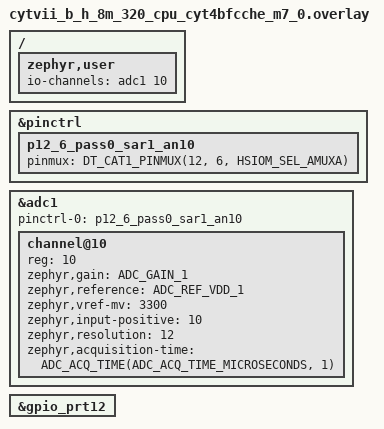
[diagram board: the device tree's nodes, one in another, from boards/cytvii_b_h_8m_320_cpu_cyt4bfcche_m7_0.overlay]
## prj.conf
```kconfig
CONFIG_ADC=y
# CONFIG_ADC_SHELL=y
# CONFIG_SHELL=y
# CONFIG_SHELL_PROMPT_UART="uart:~$ "
CONFIG_LOG=y
CONFIG_LOG_DEFAULT_LEVEL=3
CONFIG_ADC_LOG_LEVEL_WRN=y
CONFIG_COVERAGE=y

# Disable debug logging for noisy subsystems
CONFIG_MPU_LOG_LEVEL_DBG=n
CONFIG_KERNEL_LOG_LEVEL_DBG=n
CONFIG_ADC_ASYNC=n
```

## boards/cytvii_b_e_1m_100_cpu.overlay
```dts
#include <zephyr/dt-bindings/pinctrl/ifx_cat1-pinctrl.h>

/ {
	zephyr,user {
		io-channels = <&adc2 5>;
	};
};

&pinctrl {
	/* Configure P18.5 for analog input */
	p18_5_pass0_sar2_an14: p18_5_pass0_sar2_an14 {
		pinmux = <DT_CAT1_PINMUX(18, 5, HSIOM_SEL_AMUXA)>;
	};
};

&adc2 {
	#address-cells = <1>;
	#size-cells = <0>;

	pinctrl-0 = <&p18_5_pass0_sar2_an14>;
	pinctrl-names = "default";


	channel@5 {
		reg = <5>;
		zephyr,gain = "ADC_GAIN_1";
		zephyr,reference = "ADC_REF_VDD_1";
		zephyr,vref-mv = <3300>;  /* VDDA = 3.3V reference */

		zephyr,input-positive = <5>;
		zephyr,resolution = <12>;
		zephyr,acquisition-time = <ADC_ACQ_TIME(ADC_ACQ_TIME_MICROSECONDS, 1)>;
	};
};
```

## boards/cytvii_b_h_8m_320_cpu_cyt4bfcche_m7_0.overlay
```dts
/*
* Copyright (c) 2025 Linumiz GmbH
* SPDX-License-Identifier: Apache-2.0
*/

#include <zephyr/dt-bindings/pinctrl/ifx_cat1-pinctrl.h>

/ {
	zephyr,user {
		io-channels = <&adc1 10>;
	};
};

&pinctrl {
		/* Configure P12.6 for analog input */
		p12_6_pass0_sar1_an10: p12_6_pass0_sar1_an10 {
		pinmux = <DT_CAT1_PINMUX(12, 6, HSIOM_SEL_AMUXA)>;
		};
	};

&adc1 {
		#address-cells = <1>;
		#size-cells = <0>;
		pinctrl-0 = <&p12_6_pass0_sar1_an10>;
		pinctrl-names = "default";

channel@10 {
		reg = <10>;
		zephyr,gain = "ADC_GAIN_1";
		zephyr,reference = "ADC_REF_VDD_1";
		zephyr,vref-mv = <3300>;
		zephyr,input-positive = <10>;
		zephyr,resolution = <12>;
		zephyr,acquisition-time = <ADC_ACQ_TIME(ADC_ACQ_TIME_MICROSECONDS, 1)>;
	};
};

&gpio_prt12 {
	status = "okay";
};
```

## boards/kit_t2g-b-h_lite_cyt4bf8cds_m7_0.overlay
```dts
/*
 * Copyright (c) 2025 Linumiz GmbH
 * SPDX-License-Identifier: Apache-2.0
 */

#include <zephyr/dt-bindings/pinctrl/ifx_cat1-pinctrl.h>

/ {
    zephyr,user {
        io-channels = <&adc0 0>;
    };
};

&pinctrl {
    /* Configure P6.0 (VR1 Potentiometer) for analog input */
    p6_0_pass0_sar0_an0: p6_0_pass0_sar0_an0 {
        pinmux = <DT_CAT1_PINMUX(6, 0, HSIOM_SEL_AMUXA)>;
    };
};

&adc0 {
    #address-cells = <1>;
    #size-cells = <0>;

    pinctrl-0 = <&p6_0_pass0_sar0_an0>;
    pinctrl-names = "default";


    channel@0 {
        reg = <0>;
        zephyr,gain = "ADC_GAIN_1";
        zephyr,reference = "ADC_REF_VDD_1";
        zephyr,vref-mv = <3300>;  /* VDDA = 3.3V reference */

        zephyr,input-positive = <0>;  /* AN0 mapped to P6.0 (Potentiometer VR1) */ 
        zephyr,resolution = <12>;
        zephyr,acquisition-time = <ADC_ACQ_TIME(ADC_ACQ_TIME_MICROSECONDS, 1)>;
    };
};
```

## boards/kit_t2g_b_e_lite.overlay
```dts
/*
 * Copyright (c) 2025 Linumiz GmbH
 * SPDX-License-Identifier: Apache-2.0
 */

#include <zephyr/dt-bindings/pinctrl/ifx_cat1-pinctrl.h>
#include <zephyr/dt-bindings/adc/adc.h>

/ {
    zephyr,user {
        io-channels = <&adc0 0>;
    };
};

&pinctrl {
    /* Configure P6.0 for analog input */
    p6_0_pass0_sar0_an14: p6_6_pass0_sar0_an14 {
        pinmux = <DT_CAT1_PINMUX(6, 0, HSIOM_SEL_AMUXA)>;
    };
};

&adc0 {
    #address-cells = <1>;
    #size-cells = <0>;

    pinctrl-0 = <&p6_0_pass0_sar0_an14>;
    pinctrl-names = "default";


    channel@0 {
        reg = <0>;
        zephyr,gain = "ADC_GAIN_1";
        zephyr,reference = "ADC_REF_VDD_1";
        zephyr,vref-mv = <3300>;  /* VDDA = 3.3V reference */

        zephyr,input-positive = <0>;
        zephyr,resolution = <12>;
        zephyr,acquisition-time = <ADC_ACQ_TIME(ADC_ACQ_TIME_MICROSECONDS, 1)>;
    };
};
```

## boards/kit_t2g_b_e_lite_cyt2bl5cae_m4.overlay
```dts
/*
 * Copyright (c) 2025 Linumiz GmbH
 * SPDX-License-Identifier: Apache-2.0
 */

#include <zephyr/dt-bindings/pinctrl/ifx_cat1-pinctrl.h>
#include <zephyr/dt-bindings/adc/adc.h>

/ {
	zephyr,user {
		io-channels = <&adc0 0>;
	};
};

&pinctrl {
	/* Configure P6.0 for analog input */
	p6_0_pass0_sar0_an14: p6_6_pass0_sar0_an14 {
		pinmux = <DT_CAT1_PINMUX(6, 0, HSIOM_SEL_AMUXA)>;
	};
};

&adc0 {
	#address-cells = <1>;
	#size-cells = <0>;

	pinctrl-0 = <&p6_0_pass0_sar0_an14>;
	pinctrl-names = "default";


	channel@0 {
		reg = <0>;
		zephyr,gain = "ADC_GAIN_1";
		zephyr,reference = "ADC_REF_VDD_1";
		zephyr,vref-mv = <3300>;  /* VDDA = 3.3V reference */

		zephyr,input-positive = <0>;
		zephyr,resolution = <12>;
		zephyr,acquisition-time = <ADC_ACQ_TIME(ADC_ACQ_TIME_MICROSECONDS, 1)>;
	};
};
```

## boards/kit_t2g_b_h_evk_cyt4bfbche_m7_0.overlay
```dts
/*
 * Copyright (c) 2025 Linumiz GmbH
 * SPDX-License-Identifier: Apache-2.0
 */

#include <zephyr/dt-bindings/pinctrl/ifx_cat1-pinctrl.h>

/ {
    zephyr,user {
        io-channels = <&adc0 0>;
    };
};

&pinctrl {
    /* Configure P6.6 for analog input */
    p6_6_pass0_sar0_an14: p6_6_pass0_sar0_an14 {
        pinmux = <DT_CAT1_PINMUX(6, 6, HSIOM_SEL_AMUXA)>;
    };
};

&adc0 {
    #address-cells = <1>;
    #size-cells = <0>;

    pinctrl-0 = <&p6_6_pass0_sar0_an14>;
    pinctrl-names = "default";


    channel@0 {
        reg = <0>;
        zephyr,gain = "ADC_GAIN_1";
        zephyr,reference = "ADC_REF_VDD_1";
        zephyr,vref-mv = <3300>;  /* VDDA = 3.3V reference */

        zephyr,input-positive = <6>;
        zephyr,resolution = <12>;
        zephyr,acquisition-time = <ADC_ACQ_TIME(ADC_ACQ_TIME_MICROSECONDS, 1)>;
    };
};
```

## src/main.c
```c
/*
 * Copyright (c) 2020 Libre Solar Technologies GmbH
 *
 * SPDX-License-Identifier: Apache-2.0
 */

#include <inttypes.h>
#include <stddef.h>
#include <stdint.h>

#include <zephyr/device.h>
#include <zephyr/devicetree.h>
#include <zephyr/drivers/adc.h>
#include <zephyr/kernel.h>
#include <zephyr/sys/printk.h>
#include <zephyr/sys/util.h>

#if !DT_NODE_EXISTS(DT_PATH(zephyr_user)) || \
	!DT_NODE_HAS_PROP(DT_PATH(zephyr_user), io_channels)
#error "No suitable devicetree overlay specified"
#endif

#define DT_SPEC_AND_COMMA(node_id, prop, idx) \
	ADC_DT_SPEC_GET_BY_IDX(node_id, idx),

/* Data of ADC io-channels specified in devicetree. */
static const struct adc_dt_spec adc_channels[] = {
	DT_FOREACH_PROP_ELEM(DT_PATH(zephyr_user), io_channels,
			     DT_SPEC_AND_COMMA)
};

int main(void)
{
	int err;
	uint32_t count = 0;
	uint32_t buf;
	struct adc_sequence sequence = {
		.buffer = &buf,
		/* buffer size in bytes, not number of samples */
		.buffer_size = sizeof(buf),
	};

	/* Configure channels individually prior to sampling. */
	for (size_t i = 0U; i < ARRAY_SIZE(adc_channels); i++) {
		if (!adc_is_ready_dt(&adc_channels[i])) {
			printk("ADC controller device %s not ready\n", adc_channels[i].dev->name);
			return 0;
		}

		err = adc_channel_setup_dt(&adc_channels[i]);
		if (err < 0) {
			printk("Could not setup channel #%d (%d)\n", i, err);
			return 0;
		}
	}

#ifndef CONFIG_COVERAGE
	while (1) {
#else
	for (int k = 0; k < 10; k++) {
#endif
		printk("ADC reading[%u]:\n", count++);
		for (size_t i = 0U; i < ARRAY_SIZE(adc_channels); i++) {
			int32_t val_mv;

			printk("- %s, channel %d: ",
			       adc_channels[i].dev->name,
			       adc_channels[i].channel_id);

			(void)adc_sequence_init_dt(&adc_channels[i], &sequence);

			err = adc_read_dt(&adc_channels[i], &sequence);
			if (err < 0) {
				printk("Could not read (%d)\n", err);
				continue;
			}

			/*
			 * If using differential mode, the 16 bit value
			 * in the ADC sample buffer should be a signed 2's
			 * complement value.
			 */
			if (adc_channels[i].channel_cfg.differential) {
				val_mv = (int32_t)((int16_t)buf);
			} else {
				val_mv = (int32_t)buf;
			}
			printk("%"PRId32, val_mv);
			err = adc_raw_to_millivolts_dt(&adc_channels[i],
						       &val_mv);
			/* conversion to mV may not be supported, skip if not */
			if (err < 0) {
				printk(" (value in mV not available)\n");
			} else {
				printk(" = %"PRId32" mV\n", val_mv);
			}
		}

		k_sleep(K_MSEC(1000));
	}
	return 0;
}
```
